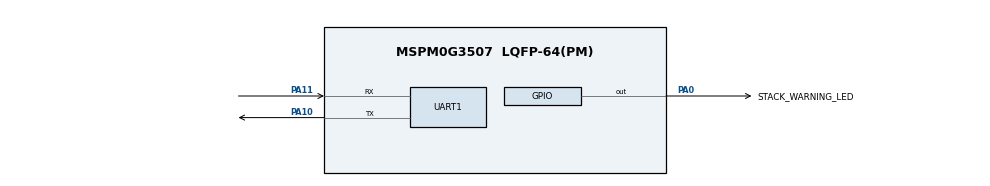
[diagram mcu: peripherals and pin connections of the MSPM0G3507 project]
/**
 * These arguments were used when this file was generated. They will be automatically applied on subsequent loads
 * via the GUI or CLI. Run CLI with '--help' for additional information on how to override these arguments.
 * @cliArgs --device "MSPM0G350X" --part "Default" --package "LQFP-64(PM)" --product "mspm0_sdk@2.10.00.04"
 * @v2CliArgs --device "MSPM0G3507" --package "LQFP-64(PM)" --product "mspm0_sdk@2.10.00.04"
 * @versions {"tool":"1.27.0+4565"}
 */

/**
 * Import the modules used in this configuration.
 */
const GPIO          = scripting.addModule("/ti/driverlib/GPIO", {}, false);
const GPIO1         = GPIO.addInstance();
const SYSCTL        = scripting.addModule("/ti/driverlib/SYSCTL");
const UART          = scripting.addModule("/ti/driverlib/UART", {}, false);
const UART1         = UART.addInstance();
const ProjectConfig = scripting.addModule("/ti/project_config/ProjectConfig");

/**
 * Write custom configuration values to the imported modules.
 */
GPIO1.$name                          = "GPIO_LEDS";
GPIO1.associatedPins[0].assignedPin  = "0";
GPIO1.associatedPins[0].$name        = "STACK_WARNING_LED";
GPIO1.associatedPins[0].assignedPort = "PORTA";
GPIO1.associatedPins[0].initialValue = "SET";
GPIO1.associatedPins[0].pin.$assign  = "PA0";

const Board = scripting.addModule("/ti/driverlib/Board", {}, false);

SYSCTL.clockTreeEn = true;

UART1.$name                    = "UART_0";
UART1.enabledInterrupts        = ["RX"];
UART1.targetBaudRate           = 115200;
UART1.peripheral.rxPin.$assign = "PA11";
UART1.peripheral.txPin.$assign = "PA10";
UART1.txPinConfig.$name        = "ti_driverlib_gpio_GPIOPinGeneric0";
UART1.rxPinConfig.$name        = "ti_driverlib_gpio_GPIOPinGeneric1";

ProjectConfig.genDisable = true;
scripting.suppress("Project Configuration File generation is disabled for this project\\. SysConfig Project Migration is not currently supported for this project\\.", ProjectConfig);

/**
 * Pinmux solution for unlocked pins/peripherals. This ensures that minor changes to the automatic solver in a future
 * version of the tool will not impact the pinmux you originally saw.  These lines can be completely deleted in order to
 * re-solve from scratch.
 */
Board.peripheral.$suggestSolution          = "DEBUGSS";
Board.peripheral.swclkPin.$suggestSolution = "PA20";
Board.peripheral.swdioPin.$suggestSolution = "PA19";
UART1.peripheral.$suggestSolution          = "UART0";
